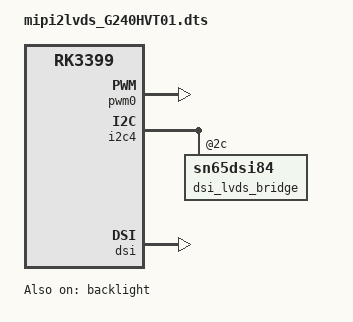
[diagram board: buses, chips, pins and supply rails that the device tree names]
/dts-v1/;
/plugin/;
/ {
	compatible = "rockchip,rk3399-excavator-linux", "rockchip,rk3399";

	fragment@0 {
		target = <&pwm0>;
		__overlay__ {
			status = "okay";
		};
	};
	fragment@1 {
		target = <&backlight>;
		__overlay__ {
			status = "okay";
                        minimal-brightness-level = <26>;
		};
	};
	fragment@2 {
		target = <&i2c4>;
		__overlay__ {
			status = "okay";
			dsi_lvds_bridge: sn65dsi84@2c {
				status = "okay";
				lvds-clk-rate = <72000000>;
				lvds-format = <2>;
				lvds-bpp = <24>;
				lvds-width-mm = <531>;
				lvds-height-mm = <299>;
				sync_delay = <33>;
                                dual-link;

				t1=<0>;
				t2=<30>;
				t3=<250>;
				t4=<160>;
				t5=<1>;
				t6=<0>;
				t7=<1000>;

				bpc=<8>;
				bus-format = <0x100a>;
				dsi,flags = <0x3>;
				dsi,format = <0>;
				dsi-lanes = <4>;

				display-timings {
					lvds {
						clock-frequency = <144000000>;
						hactive = <1920>;
						vactive = <1080>;
						hfront-porch = <80>;
						hback-porch = <80>;
						hsync-len = <40>;
						vfront-porch = <15>;
						vsync-len = <10>;
						vback-porch = <15>;
						hsync-active = <0>;
						vsync-active = <0>;
						de-active = <1>;
						pixelclk-active = <0>;
					};
				};
			};
		};
	};
	fragment@3 {
		target = <&dsi>;
		__overlay__ {
			status = "okay";
			mipi_panel: mipi-panel {
				status = "disabled";
			};
		};
	};
        fragment@4 {
		target = <&pinctrl>;
		__overlay__ {
			gpio_init_config {
				gpio_init: gpio-init {
                                           rockchip,pins =
                                                <1 8 0  &pcfg_pull_none>;
				};
			};
		};
	};

};
